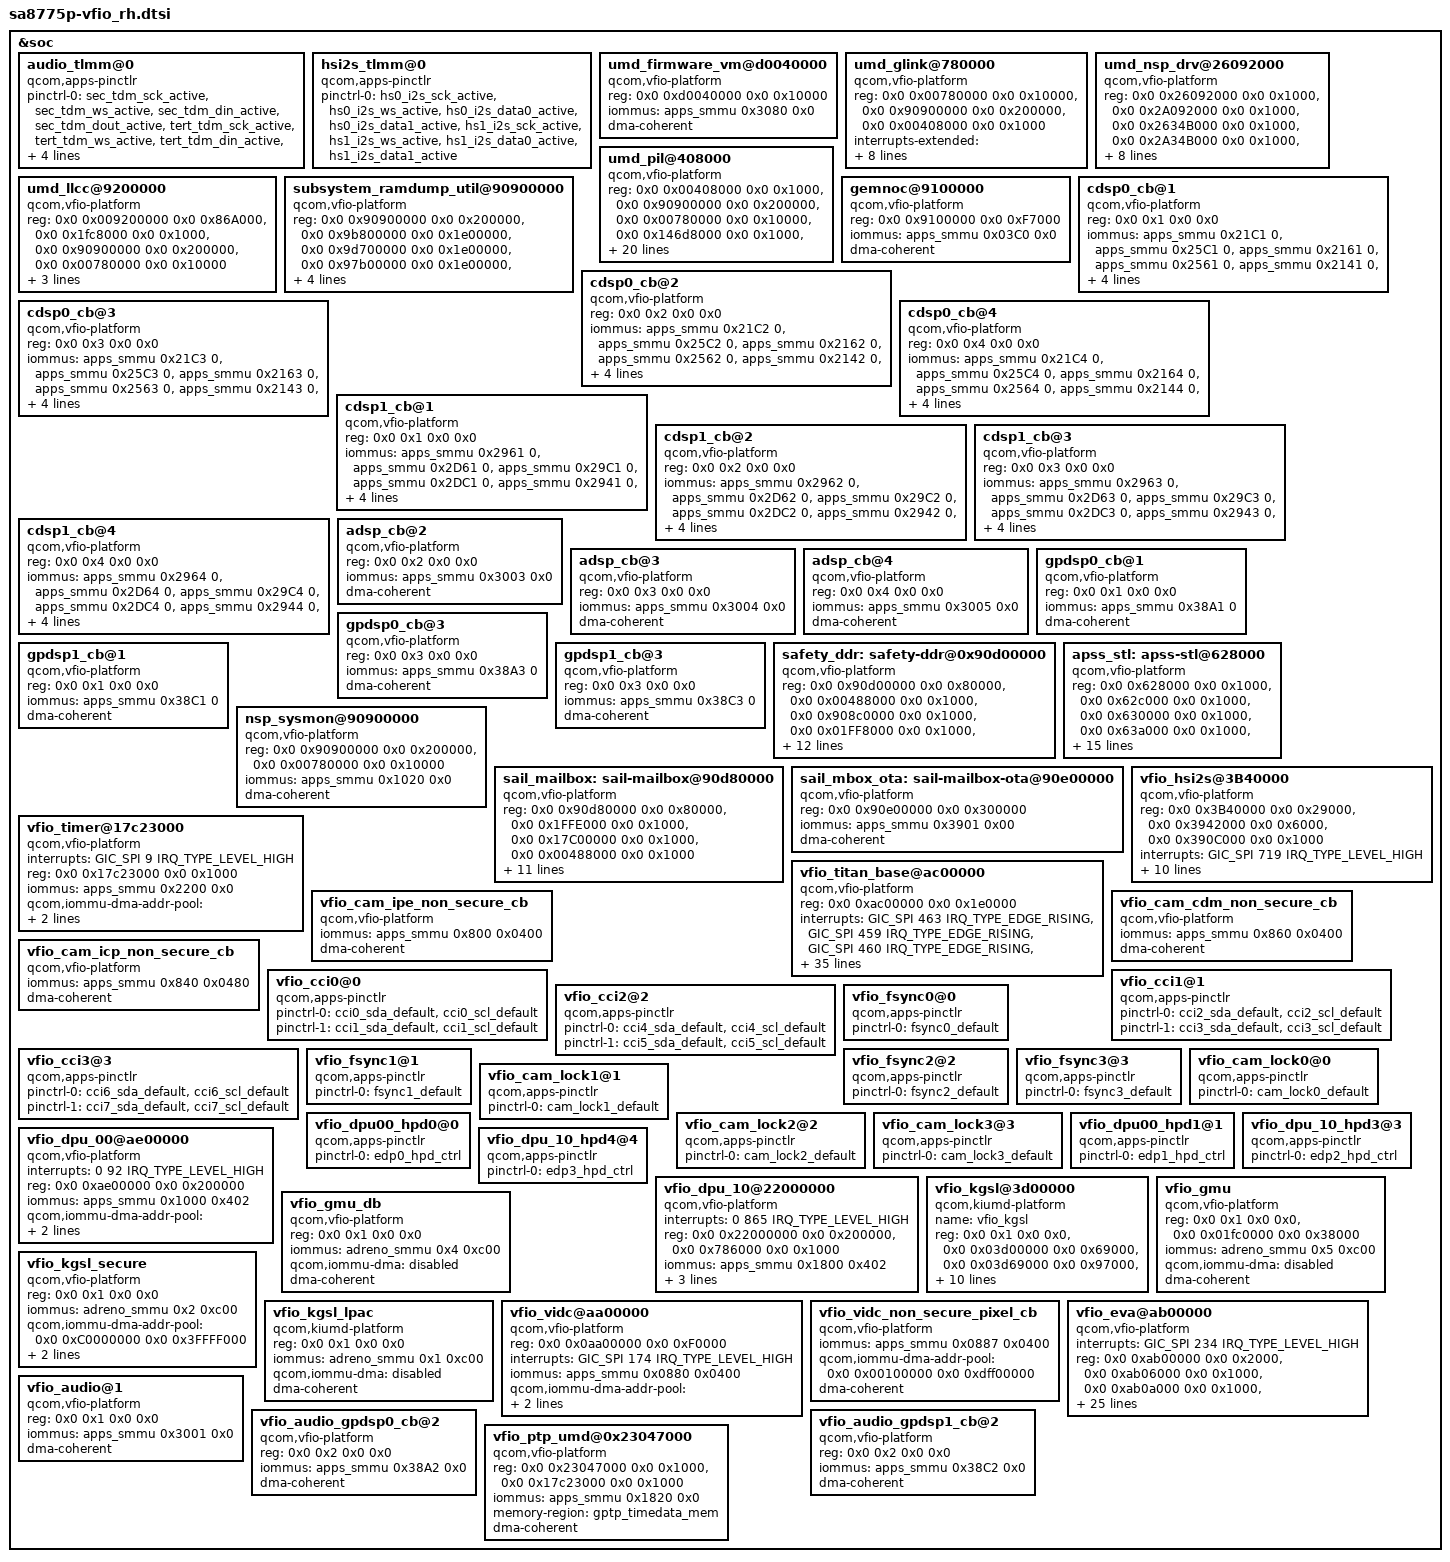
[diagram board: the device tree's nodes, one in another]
// SPDX-License-Identifier: BSD-3-Clause
/*
* Copyright (c) 2024 Qualcomm Innovation Center, Inc. All rights reserved.
*/

&soc {
	audio_tlmm@0 {
		compatible = "qcom,apps-pinctlr";
		pinctrl-names = "default";
		pinctrl-0 = <&sec_tdm_sck_active &sec_tdm_ws_active &sec_tdm_din_active &sec_tdm_dout_active &tert_tdm_sck_active &tert_tdm_ws_active &tert_tdm_din_active &tert_tdm_dout_active &hs2_i2s_sck_active &hs2_i2s_ws_active &hs2_i2s_data0_active &hs2_i2s_data1_active &audio_internal_mclk1_active>;
	};

	hsi2s_tlmm@0 {
		compatible = "qcom,apps-pinctlr";
		pinctrl-names = "default";
		pinctrl-0 = <&hs0_i2s_sck_active &hs0_i2s_ws_active &hs0_i2s_data0_active &hs0_i2s_data1_active &hs1_i2s_sck_active &hs1_i2s_ws_active &hs1_i2s_data0_active &hs1_i2s_data1_active>;
	};

	umd_firmware_vm@d0040000 {
		compatible = "qcom,vfio-platform";
		reg = <0x0 0xd0040000 0x0 0x10000>;
		iommus = <&apps_smmu 0x3080 0x0>;
		dma-coherent;
	};

	umd_glink@780000 {
		compatible = "qcom,vfio-platform";
		reg = <0x0 0x00780000 0x0 0x10000>,
			<0x0 0x90900000 0x0 0x200000>,
			<0x0 0x00408000 0x0 0x1000>;

		interrupts-extended = <&ipcc IPCC_CLIENT_LPASS IPCC_MPROC_SIGNAL_GLINK_QMP IRQ_TYPE_EDGE_RISING>,
				<&ipcc IPCC_CLIENT_CDSP IPCC_MPROC_SIGNAL_GLINK_QMP IRQ_TYPE_EDGE_RISING>,
				<&ipcc IPCC_CLIENT_NSP1  IPCC_MPROC_SIGNAL_GLINK_QMP IRQ_TYPE_EDGE_RISING>,
				<&ipcc IPCC_CLIENT_SLPI  IPCC_MPROC_SIGNAL_GLINK_QMP IRQ_TYPE_EDGE_RISING>,
				<&ipcc IPCC_CLIENT_GPDSP0  IPCC_MPROC_SIGNAL_GLINK_QMP IRQ_TYPE_EDGE_RISING>,
				<&ipcc IPCC_CLIENT_GPDSP1  IPCC_MPROC_SIGNAL_GLINK_QMP IRQ_TYPE_EDGE_RISING>;

		iommus = <&apps_smmu 0x5E0 0x0>;
		dma-coherent;
	};

	umd_nsp_drv@26092000 {
		compatible = "qcom,vfio-platform";
		reg = <0x0 0x26092000 0x0 0x1000>,
			<0x0 0x2A092000 0x0 0x1000>,
			<0x0 0x2634B000 0x0 0x1000>,
			<0x0 0x2A34B000 0x0 0x1000>,
			<0x0 0x26350000 0x0 0x1000>,
			<0x0 0x2A350000 0x0 0x1000>;
		interrupts = <GIC_SPI 867 IRQ_TYPE_LEVEL_HIGH>,
			<GIC_SPI 454 IRQ_TYPE_LEVEL_HIGH>,
			<GIC_SPI 578 IRQ_TYPE_LEVEL_HIGH>,
			<GIC_SPI 798 IRQ_TYPE_LEVEL_HIGH>;
		iommus = <&apps_smmu 0x0D20 0x0>;
		dma-coherent;
	};

	umd_pil@408000 {
		compatible = "qcom,vfio-platform";
		reg = <0x0 0x00408000 0x0 0x1000>,
			<0x0 0x90900000 0x0 0x200000>,
			<0x0 0x00780000 0x0 0x10000>,
			<0x0 0x146d8000 0x0 0x1000>,
			<0x0 0x95700000 0x0 0x500000>,
			<0x0 0x95c00000 0x0 0x1e00000>,
			<0x0 0x9b800000 0x0 0x1e00000>,
			<0x0 0x9fc00000 0x0 0x700000>,
			<0x0 0x9d700000 0x0 0x1e00000>,
			<0x0 0x97b00000 0x0 0x1e00000>,
			<0x0 0x99900000 0x0 0x1e00000>,
			<0x0 0x9D600000 0x0 0x800000>;

		interrupts-extended = <&ipcc IPCC_CLIENT_LPASS IPCC_MPROC_SIGNAL_SMP2P IRQ_TYPE_EDGE_RISING>,
				<&ipcc IPCC_CLIENT_CDSP  IPCC_MPROC_SIGNAL_SMP2P IRQ_TYPE_EDGE_RISING>,
				<&ipcc IPCC_CLIENT_NSP1  IPCC_MPROC_SIGNAL_SMP2P IRQ_TYPE_EDGE_RISING>,
				<&ipcc IPCC_CLIENT_SLPI  IPCC_MPROC_SIGNAL_SMP2P IRQ_TYPE_EDGE_RISING>,
				<&ipcc IPCC_CLIENT_GPDSP0  IPCC_MPROC_SIGNAL_SMP2P IRQ_TYPE_EDGE_RISING>,
				<&ipcc IPCC_CLIENT_GPDSP1  IPCC_MPROC_SIGNAL_SMP2P IRQ_TYPE_EDGE_RISING>,
				<&intc GIC_SPI 486 IRQ_TYPE_LEVEL_HIGH>,
				<&intc GIC_SPI 768 IRQ_TYPE_LEVEL_HIGH>,
				<&intc GIC_SPI 624 IRQ_TYPE_LEVEL_HIGH>;

		iommus = <&apps_smmu 0x2A00 0x0>;
		dma-coherent;
	};

	//Add LLCC node for vfio probe.
	umd_llcc@9200000 {
		compatible = "qcom,vfio-platform";
		reg = <0x0 0x009200000 0x0 0x86A000>,
			<0x0 0x1fc8000 0x0 0x1000>,
			<0x0 0x90900000 0x0 0x200000>,
			<0x0 0x00780000 0x0 0x10000>;
		interrupts = <GIC_SPI 580 IRQ_TYPE_LEVEL_HIGH>;
		iommus = <&apps_smmu 0x2E00 0x0>;
		dma-coherent;
	};

	subsystem_ramdump_util@90900000 {
		compatible = "qcom,vfio-platform";
		reg = <0x0 0x90900000 0x0 0x200000>,
			<0x0 0x9b800000 0x0 0x1e00000>,
			<0x0 0x9d700000 0x0 0x1e00000>,
			<0x0 0x97b00000 0x0 0x1e00000>,
			<0x0 0x99900000 0x0 0x1e00000>,
			<0x0 0x95c00000 0x0 0x1e00000>;

		iommus = <&adreno_smmu 0x407 0xc00>;
		dma-coherent;
	};

	gemnoc@9100000 {
		compatible = "qcom,vfio-platform";
		reg = <0x0 0x9100000 0x0 0xF7000>;
		iommus = <&apps_smmu 0x03C0 0x0>;
		dma-coherent;
	};

	cdsp0_cb@1 {
		compatible = "qcom,vfio-platform";
		reg = <0x0 0x1 0x0 0x0>;
		iommus = <&apps_smmu 0x21C1 0>,
			<&apps_smmu 0x25C1 0>,
			<&apps_smmu 0x2161 0>,
			<&apps_smmu 0x2561 0>,
			<&apps_smmu 0x2141 0>,
			<&apps_smmu 0x2541 0>,
			<&apps_smmu 0x21E1 0>,
			<&apps_smmu 0x25E1 0>,
			<&apps_smmu 0x2181 0>,
			<&apps_smmu 0x2581 0>;
		dma-coherent;
	};

	cdsp0_cb@2 {
		compatible = "qcom,vfio-platform";
		reg = <0x0 0x2 0x0 0x0>;
		iommus = <&apps_smmu 0x21C2 0>,
			<&apps_smmu 0x25C2 0>,
			<&apps_smmu 0x2162 0>,
			<&apps_smmu 0x2562 0>,
			<&apps_smmu 0x2142 0>,
			<&apps_smmu 0x2542 0>,
			<&apps_smmu 0x21E2 0>,
			<&apps_smmu 0x25E2 0>,
			<&apps_smmu 0x2182 0>,
			<&apps_smmu 0x2582 0>;
		dma-coherent;
	};

	cdsp0_cb@3 {
		compatible = "qcom,vfio-platform";
		reg = <0x0 0x3 0x0 0x0>;
		iommus = <&apps_smmu 0x21C3 0>,
			<&apps_smmu 0x25C3 0>,
			<&apps_smmu 0x2163 0>,
			<&apps_smmu 0x2563 0>,
			<&apps_smmu 0x2143 0>,
			<&apps_smmu 0x2543 0>,
			<&apps_smmu 0x21E3 0>,
			<&apps_smmu 0x25E3 0>,
			<&apps_smmu 0x2183 0>,
			<&apps_smmu 0x2583 0>;
		dma-coherent;
	};

	cdsp0_cb@4 {
		compatible = "qcom,vfio-platform";
		reg = <0x0 0x4 0x0 0x0>;
		iommus = <&apps_smmu 0x21C4 0>,
			<&apps_smmu 0x25C4 0>,
			<&apps_smmu 0x2164 0>,
			<&apps_smmu 0x2564 0>,
			<&apps_smmu 0x2144 0>,
			<&apps_smmu 0x2544 0>,
			<&apps_smmu 0x21E4 0>,
			<&apps_smmu 0x25E4 0>,
			<&apps_smmu 0x2184 0>,
			<&apps_smmu 0x2584 0>;
		dma-coherent;
	};

	cdsp1_cb@1 {
		compatible = "qcom,vfio-platform";
		reg = <0x0 0x1 0x0 0x0>;
		iommus = <&apps_smmu 0x2961 0>,
			<&apps_smmu 0x2D61 0>,
			<&apps_smmu 0x29C1 0>,
			<&apps_smmu 0x2DC1 0>,
			<&apps_smmu 0x2941 0>,
			<&apps_smmu 0x2D41 0>,
			<&apps_smmu 0x2981 0>,
			<&apps_smmu 0x2D81 0>,
			<&apps_smmu 0x29E1 0>,
			<&apps_smmu 0x2DE1 0>;
		dma-coherent;
	};

	cdsp1_cb@2 {
		compatible = "qcom,vfio-platform";
		reg = <0x0 0x2 0x0 0x0>;
		iommus = <&apps_smmu 0x2962 0>,
			<&apps_smmu 0x2D62 0>,
			<&apps_smmu 0x29C2 0>,
			<&apps_smmu 0x2DC2 0>,
			<&apps_smmu 0x2942 0>,
			<&apps_smmu 0x2D42 0>,
			<&apps_smmu 0x29E2 0>,
			<&apps_smmu 0x2DE2 0>,
			<&apps_smmu 0x2982 0>,
			<&apps_smmu 0x2D82 0>;
		dma-coherent;
	};

	cdsp1_cb@3 {
		compatible = "qcom,vfio-platform";
		reg = <0x0 0x3 0x0 0x0>;
		iommus = <&apps_smmu 0x2963 0>,
			<&apps_smmu 0x2D63 0>,
			<&apps_smmu 0x29C3 0>,
			<&apps_smmu 0x2DC3 0>,
			<&apps_smmu 0x2943 0>,
			<&apps_smmu 0x2D43 0>,
			<&apps_smmu 0x29E3 0>,
			<&apps_smmu 0x2DE3 0>,
			<&apps_smmu 0x2983 0>,
			<&apps_smmu 0x2D83 0>;
		dma-coherent;
	};

	cdsp1_cb@4 {
		compatible = "qcom,vfio-platform";
		reg = <0x0 0x4 0x0 0x0>;
		iommus = <&apps_smmu 0x2964 0>,
			<&apps_smmu 0x2D64 0>,
			<&apps_smmu 0x29C4 0>,
			<&apps_smmu 0x2DC4 0>,
			<&apps_smmu 0x2944 0>,
			<&apps_smmu 0x2D44 0>,
			<&apps_smmu 0x29E4 0>,
			<&apps_smmu 0x2DE4 0>,
			<&apps_smmu 0x2984 0>,
			<&apps_smmu 0x2D84 0>;
		dma-coherent;
	};

	adsp_cb@2 {
		compatible = "qcom,vfio-platform";
		reg = <0x0 0x2 0x0 0x0>;
		iommus = <&apps_smmu 0x3003 0x0>;
		dma-coherent;
	};

	adsp_cb@3 {
		compatible = "qcom,vfio-platform";
		reg = <0x0 0x3 0x0 0x0>;
		iommus = <&apps_smmu 0x3004 0x0>;
		dma-coherent;
	};

	adsp_cb@4 {
		compatible = "qcom,vfio-platform";
		reg = <0x0 0x4 0x0 0x0>;
		iommus = <&apps_smmu 0x3005 0x0>;
		dma-coherent;
	};

	gpdsp0_cb@1 {
		compatible = "qcom,vfio-platform";
		reg = <0x0 0x1 0x0 0x0>;
		iommus = <&apps_smmu 0x38A1 0>;
		dma-coherent;
	};

	gpdsp0_cb@3 {
		compatible = "qcom,vfio-platform";
		reg = <0x0 0x3 0x0 0x0>;
		iommus = <&apps_smmu 0x38A3 0>;
		dma-coherent;
	};

	gpdsp1_cb@1 {
		compatible = "qcom,vfio-platform";
		reg = <0x0 0x1 0x0 0x0>;
		iommus = <&apps_smmu 0x38C1 0>;
		dma-coherent;
	};

	gpdsp1_cb@3 {
		compatible = "qcom,vfio-platform";
		reg = <0x0 0x3 0x0 0x0>;
		iommus = <&apps_smmu 0x38C3 0>;
		dma-coherent;
	};

	safety_ddr: safety-ddr@0x90d00000 {
		compatible = "qcom,vfio-platform";
		reg = <0x0 0x90d00000 0x0 0x80000>,
			<0x0 0x00488000 0x0 0x1000>,
			<0x0 0x908c0000 0x0 0x1000>,
			<0x0 0x01FF8000 0x0 0x1000>,
			<0x0 0x01FFA000 0x0 0x1000>,
			<0x0 0xDB1DA000 0x0 0x2000>,
			<0x0 0xDB1DB000 0x0 0x1000>,
			<0x0 0x17D00000 0x0 0x1000>,
			<0x0 0x090BD000 0x0 0x1000>;
		iommus = <&apps_smmu 0x3903 0x0>;
		interrupts-extended = <&ipcc1 IPCC_CLIENT_SAIL0 0x1 IRQ_TYPE_EDGE_RISING>,
				      <&ipcc1 IPCC_CLIENT_SAIL1 0x1 IRQ_TYPE_EDGE_RISING>,
				      <&ipcc1 IPCC_CLIENT_SAIL2 0x1 IRQ_TYPE_EDGE_RISING>,
				      <&ipcc1 IPCC_CLIENT_SAIL3 0x1 IRQ_TYPE_EDGE_RISING>;
		dma-coherent;
	};

	apss_stl: apss-stl@628000 {
		compatible = "qcom,vfio-platform";
		reg = <0x0 0x628000 0x0 0x1000>,
			<0x0 0x62c000 0x0 0x1000>,
			<0x0 0x630000 0x0 0x1000>,
			<0x0 0x63a000 0x0 0x1000>,
			<0x0 0x63e000 0x0 0x1000>,
			<0x0 0x3d9a000 0x0 0x1000>,
			<0x0 0x18290000 0x0 0x1000>,
			<0x0 0x18292000 0x0 0x1000>,
			<0x0 0x18294000 0x0 0x1000>,
			<0x0 0x18296000 0x0 0x1000>,
			<0x0 0x18390000 0x0 0x1000>,
			<0x0 0x183a0000 0x0 0x1000>,
			<0x0 0x18420000 0x0 0x1000>,
			<0x0 0x18421000 0x0 0x1000>,
			<0x0 0x18422000 0x0 0x1000>,
			<0x0 0x18423000 0x0 0x1000>,
			<0x0 0x17C21000 0x0 0x1000>;
		iommus = <&apps_smmu 0x3902 0x0>;
		dma-coherent;
	};

	nsp_sysmon@90900000 {
		compatible = "qcom,vfio-platform";
		reg = <0x0 0x90900000 0x0 0x200000>,
			<0x0 0x00780000 0x0 0x10000>;
		iommus = <&apps_smmu 0x1020 0x0>;
		dma-coherent;
	};

	sail_mailbox: sail-mailbox@90d80000 {
		compatible = "qcom,vfio-platform";
		reg = <0x0 0x90d80000 0x0 0x80000>,
		      <0x0 0x1FFE000 0x0 0x1000>,
		      <0x0 0x17C00000 0x0 0x1000>,
		      <0x0 0x00488000 0x0 0x1000>;
		interrupts-extended = <&ipcc1 IPCC_CLIENT_SAIL0 0x2 IRQ_TYPE_EDGE_RISING>,
				      <&ipcc1 IPCC_CLIENT_SAIL0 0x3 IRQ_TYPE_EDGE_RISING>,
				      <&ipcc1 IPCC_CLIENT_SAIL0 0x4 IRQ_TYPE_EDGE_RISING>,
				      <&ipcc1 IPCC_CLIENT_SAIL0 0x5 IRQ_TYPE_EDGE_RISING>,
				      <&ipcc1 IPCC_CLIENT_SAIL0 0x6 IRQ_TYPE_EDGE_RISING>,
				      <&ipcc1 IPCC_CLIENT_SAIL0 0x7 IRQ_TYPE_EDGE_RISING>,
				      <&ipcc1 IPCC_CLIENT_SAIL2 0x8 IRQ_TYPE_EDGE_RISING>,
				      <&ipcc1 IPCC_CLIENT_SAIL1 0x9 IRQ_TYPE_EDGE_RISING>;
		iommus = <&apps_smmu 0x3900 0x00>;
		dma-coherent;
	};

	sail_mbox_ota: sail-mailbox-ota@90e00000 {
		compatible = "qcom,vfio-platform";
		reg = <0x0 0x90e00000 0x0 0x300000>;
		iommus = <&apps_smmu 0x3901 0x00>;
		dma-coherent;
	};

	vfio_hsi2s@3B40000 {
		compatible = "qcom,vfio-platform";
		reg = <0x0 0x3B40000 0x0 0x29000>,
		    <0x0 0x3942000 0x0 0x6000>,
		    <0x0 0x390C000 0x0 0x1000>;
		reg-names = "lpa_if", "lpass_core_cc_hs_if", "lpass_core_cc_i2s_if_ctl";
		interrupts = <GIC_SPI 719 IRQ_TYPE_LEVEL_HIGH>;
		number-of-rate-detectors = <2>;
		rate-detector-interfaces = <0 1>;
		number-of-interfaces = <2>;
		qcom,smmu-version = <2>;
		qcom,smmu-enabled;
		iommus = <&apps_smmu 0x303C 0x1>,
		       <&apps_smmu 0x303A 0x4>,
		       <&apps_smmu 0x303B 0x0>;
		qcom,iommu-dma-addr-pool = <0x0 0x0 0x0 0xFFFFFFFF>;
		dma-coherent;
	};

	vfio_timer@17c23000 {
		compatible = "qcom,vfio-platform";
		interrupts = <GIC_SPI 9 IRQ_TYPE_LEVEL_HIGH>;
		reg = <0x0 0x17c23000 0x0 0x1000>;
		iommus = <&apps_smmu 0x2200 0x0>;
		qcom,iommu-dma-addr-pool = <0x0 0x60002000 0x0 0x1FFFE000>;
		dma-coherent;
	};

	vfio_titan_base@ac00000 {
		compatible = "qcom,vfio-platform";
		reg = <0x0 0xac00000 0x0 0x1e0000>;
		interrupts = <GIC_SPI 463 IRQ_TYPE_EDGE_RISING>,
			<GIC_SPI 459 IRQ_TYPE_EDGE_RISING>,
			<GIC_SPI 460 IRQ_TYPE_EDGE_RISING>,
			<GIC_SPI 271 IRQ_TYPE_EDGE_RISING>,
			<GIC_SPI 651 IRQ_TYPE_EDGE_RISING>,
			<GIC_SPI 771 IRQ_TYPE_EDGE_RISING>,
			<GIC_SPI 477 IRQ_TYPE_EDGE_RISING>,
			<GIC_SPI 478 IRQ_TYPE_EDGE_RISING>,
			<GIC_SPI 479 IRQ_TYPE_EDGE_RISING>,
			<GIC_SPI 448 IRQ_TYPE_EDGE_RISING>,
			<GIC_SPI 469 IRQ_TYPE_EDGE_RISING>,
			<GIC_SPI 360 IRQ_TYPE_EDGE_RISING>,
			<GIC_SPI 761 IRQ_TYPE_EDGE_RISING>,
			<GIC_SPI 760 IRQ_TYPE_EDGE_RISING>,
			<GIC_SPI 605 IRQ_TYPE_EDGE_RISING>,
			<GIC_SPI 465 IRQ_TYPE_EDGE_RISING>,
			<GIC_SPI 467 IRQ_TYPE_EDGE_RISING>,
			<GIC_SPI 563 IRQ_TYPE_EDGE_RISING>,
			<GIC_SPI 562 IRQ_TYPE_EDGE_RISING>,
			<GIC_SPI 468 IRQ_TYPE_EDGE_RISING>,
			<GIC_SPI 359 IRQ_TYPE_EDGE_RISING>,
			<GIC_SPI 759 IRQ_TYPE_EDGE_RISING>,
			<GIC_SPI 758 IRQ_TYPE_EDGE_RISING>,
			<GIC_SPI 604 IRQ_TYPE_EDGE_RISING>,
			<GIC_SPI 565 IRQ_TYPE_EDGE_RISING>,
			<GIC_SPI 564 IRQ_TYPE_EDGE_RISING>,
			<GIC_SPI 545 IRQ_TYPE_EDGE_RISING>,
			<GIC_SPI 546 IRQ_TYPE_EDGE_RISING>,
			<GIC_SPI 547 IRQ_TYPE_EDGE_RISING>,
			<GIC_SPI 470 IRQ_TYPE_EDGE_RISING>,
			<GIC_SPI 471 IRQ_TYPE_EDGE_RISING>,
			<GIC_SPI 543 IRQ_TYPE_EDGE_RISING>,
			<GIC_SPI 544 IRQ_TYPE_EDGE_RISING>,
			<GIC_SPI 567 IRQ_TYPE_EDGE_RISING>,
			<GIC_SPI 566 IRQ_TYPE_EDGE_RISING>,
			<GIC_SPI 366 IRQ_TYPE_EDGE_RISING>;
		iommus = <&apps_smmu 0x3400 0x0020>;
		dma-coherent;
	};

	vfio_cam_ipe_non_secure_cb {
		compatible = "qcom,vfio-platform";
		iommus = <&apps_smmu 0x800 0x0400>;
		dma-coherent;
	};

	vfio_cam_cdm_non_secure_cb {
		compatible = "qcom,vfio-platform";
		iommus = <&apps_smmu 0x860 0x0400>;
		dma-coherent;
	};

	vfio_cam_icp_non_secure_cb {
		compatible = "qcom,vfio-platform";
		iommus = <&apps_smmu 0x840 0x0480>;
		dma-coherent;
	};

	vfio_cci0@0 {
		compatible = "qcom,apps-pinctlr";
		pinctrl-names = "default","default";
		pinctrl-0 = <&cci0_sda_default &cci0_scl_default>;
		pinctrl-1 = <&cci1_sda_default &cci1_scl_default>;
	};

	vfio_cci1@1 {
		compatible = "qcom,apps-pinctlr";
		pinctrl-names = "default","default";
		pinctrl-0 = <&cci2_sda_default &cci2_scl_default>;
		pinctrl-1 = <&cci3_sda_default &cci3_scl_default>;
	};

	vfio_cci2@2 {
		compatible = "qcom,apps-pinctlr";
		pinctrl-names = "default","default";
		pinctrl-0 = <&cci4_sda_default &cci4_scl_default>;
		pinctrl-1 = <&cci5_sda_default &cci5_scl_default>;
	};

	vfio_cci3@3 {
		compatible = "qcom,apps-pinctlr";
		pinctrl-names = "default","default";
		pinctrl-0 = <&cci6_sda_default &cci6_scl_default>;
		pinctrl-1 = <&cci7_sda_default &cci7_scl_default>;
	};

	vfio_fsync0@0 {
		compatible = "qcom,apps-pinctlr";
		pinctrl-names = "default";
		pinctrl-0 = <&fsync0_default>;
	};

	vfio_fsync1@1 {
		compatible = "qcom,apps-pinctlr";
		pinctrl-names = "default";
		pinctrl-0 = <&fsync1_default>;
	};

	vfio_fsync2@2 {
		compatible = "qcom,apps-pinctlr";
		pinctrl-names = "default";
		pinctrl-0 = <&fsync2_default>;
	};

	vfio_fsync3@3 {
		compatible = "qcom,apps-pinctlr";
		pinctrl-names = "default";
		pinctrl-0 = <&fsync3_default>;
	};

	vfio_cam_lock0@0 {
		compatible = "qcom,apps-pinctlr";
		pinctrl-names = "default";
		pinctrl-0 = <&cam_lock0_default>;
	};

	vfio_cam_lock1@1 {
		compatible = "qcom,apps-pinctlr";
		pinctrl-names = "default";
		pinctrl-0 = <&cam_lock1_default>;
	};

	vfio_cam_lock2@2 {
		compatible = "qcom,apps-pinctlr";
		pinctrl-names = "default";
		pinctrl-0 = <&cam_lock2_default>;
	};

	vfio_cam_lock3@3 {
		compatible = "qcom,apps-pinctlr";
		pinctrl-names = "default";
		pinctrl-0 = <&cam_lock3_default>;
	};

	vfio_dpu00_hpd0@0 {
		compatible = "qcom,apps-pinctlr";
		pinctrl-names = "default";
		pinctrl-0 = <&edp0_hpd_ctrl>;
	};

	vfio_dpu00_hpd1@1 {
		compatible = "qcom,apps-pinctlr";
		pinctrl-names = "default";
		pinctrl-0 = <&edp1_hpd_ctrl>;
	};

	vfio_dpu_00@ae00000 {
		compatible = "qcom,vfio-platform";
		interrupts = <0 92 IRQ_TYPE_LEVEL_HIGH>;
		reg = <0x0 0xae00000 0x0 0x200000>;
		iommus = <&apps_smmu 0x1000 0x402>;
		qcom,iommu-dma-addr-pool = <0x0 0x0 0x0 0xffffffff>;
		dma-coherent;
	};

	vfio_dpu_10_hpd3@3 {
		compatible = "qcom,apps-pinctlr";
		pinctrl-names = "default";
		pinctrl-0 = <&edp2_hpd_ctrl>;
	};

	vfio_dpu_10_hpd4@4 {
		compatible = "qcom,apps-pinctlr";
		pinctrl-names = "default";
		pinctrl-0 = <&edp3_hpd_ctrl>;
	};

	vfio_dpu_10@22000000 {
		compatible = "qcom,vfio-platform";
		interrupts = <0 865 IRQ_TYPE_LEVEL_HIGH>;
		reg = <0x0 0x22000000 0x0 0x200000>,
			<0x0 0x786000 0x0 0x1000>;
		iommus = <&apps_smmu 0x1800 0x402>;
		qcom,iommu-dma-addr-pool = <0x0 0x0 0x0 0xffffffff>;
		dma-coherent;
	};

	vfio_kgsl@3d00000 {
		name = "vfio_kgsl";
		compatible = "qcom,kiumd-platform";

		reg = <0x0 0x1 0x0 0x0>,
			<0x0 0x03d00000 0x0 0x69000>,
			<0x0 0x03d69000 0x0 0x97000>,
			<0x0 0x0b210000 0x0 0x400000>,
			<0x0 0x00780000 0x0 0x7000>,
			<0x0 0x01fc8000 0x0 0x1000>,
			<0x0 0x01fc0000 0x0 0x30000>;
		reg-names = "dummy", "gpu_reg", "gmu_reg",
			"rpmh_pdc", "security_control_core",
			"tcsr_hwver_reg", "tcsr_tcsr_reg";

		interrupts = <0 300 IRQ_TYPE_LEVEL_HIGH>,
			<0 304 IRQ_TYPE_LEVEL_HIGH>,
			<0 305 IRQ_TYPE_LEVEL_HIGH>;
		interrupt-names = "kgsl_3d0_irq", "kgsl_hfi_irq",
				"kgsl_gmu_irq";

		iommus = <&adreno_smmu 0x0 0xc00>;
		qcom,iommu-dma = "disabled";
		dma-coherent;
	};

	vfio_gmu {
		compatible = "qcom,vfio-platform";
		reg = <0x0 0x1 0x0 0x0>,
			<0x0 0x01fc0000 0x0 0x38000>;
		reg-names = "dummy", "tcsr_tcsr_reg";
		iommus = <&adreno_smmu 0x5 0xc00>;
		qcom,iommu-dma = "disabled";
		dma-coherent;
	};

	vfio_gmu_db {
		compatible = "qcom,vfio-platform";
		reg = <0x0 0x1 0x0 0x0>;
		iommus = <&adreno_smmu 0x4 0xc00>;
		qcom,iommu-dma = "disabled";
		dma-coherent;
	};

	vfio_kgsl_secure {
		compatible = "qcom,vfio-platform";
		reg = <0x0 0x1 0x0 0x0>;
		// switch to secure CB once ready
		iommus = <&adreno_smmu 0x2 0xc00>;
		qcom,iommu-dma-addr-pool = <0x0 0xC0000000 0x0 0x3FFFF000>;
		qcom,iommu-dma = "disabled";
		dma-coherent;
	};

	vfio_kgsl_lpac {
		compatible = "qcom,kiumd-platform";
		reg = <0x0 0x1 0x0 0x0>;
		iommus = <&adreno_smmu 0x1 0xc00>;
		qcom,iommu-dma = "disabled";
		dma-coherent;
	};

	vfio_vidc@aa00000 {
		compatible = "qcom,vfio-platform";
		reg = <0x0 0x0aa00000 0x0 0xF0000>;
		interrupts = <GIC_SPI 174 IRQ_TYPE_LEVEL_HIGH>;

		/* MMU: non_secure_cb */
		iommus = <&apps_smmu 0x0880 0x0400>;
		qcom,iommu-dma-addr-pool = <0x0 0x25800000 0x0 0xba800000>;
		dma-coherent;
	};

	vfio_vidc_non_secure_pixel_cb {
		compatible = "qcom,vfio-platform";
		iommus = <&apps_smmu 0x0887 0x0400>;
		qcom,iommu-dma-addr-pool = <0x0 0x00100000 0x0 0xdff00000>;
		dma-coherent;
	};

	vfio_eva@ab00000 {
		compatible = "qcom,vfio-platform";
		interrupts = <GIC_SPI 234 IRQ_TYPE_LEVEL_HIGH>;
		reg = <0x0 0xab00000 0x0 0x2000>,    //CVP0_CVP_TOP_PHYS_ADDR
		      <0x0 0xab06000 0x0 0x1000>,    //CVP_DMA0_PHYS_ADDR
		      <0x0 0xab0a000 0x0 0x1000>,    //CVP_FDU0_ECC_PHYS_ADDR <0xab0a000 0x400>
		      <0x0 0xab0a000 0x0 0x3000>,    //CVP_DMA0_ECC_PHYS_ADDR <0xab0a800 0x2000>
		      <0x0 0xab0c000 0x0 0x3000>,    //CVP_MPU0_ECC_PHYS_ADDR <0xab0c800 0x2000>
		      <0x0 0xab20000 0x0 0x2000>,    //CVP1_CVP_TOP_PHYS_ADDR
		      <0x0 0xab26000 0x0 0x1000>,    //CVP_DMA1_PHYS_ADDR
		      <0x0 0xab2a000 0x0 0x1000>,    //CVP_FDU1_ECC_PHYS_ADDR <0xab2a000 0x400>
		      <0x0 0xab2a000 0x0 0x3000>,    //CVP_DMA1_ECC_PHYS_ADDR <0xab2a800 0x2000>
		      <0x0 0xab2c000 0x0 0x3000>,    //CVP_MPU1_ECC_PHYS_ADDR <0xab2c800 0x2000>
		      <0x0 0xab10000 0x0 0x10000>,   //CVP_NOC_VIDEO_B_PHYS_ADDR <0xab10000 0xf580>
		      <0x0 0xab1F000 0x0 0x1000>,    //AON_CVP_NOC_RESET_PHYS_ADDR <0xab1F800 0x800>
		      <0x0 0xabb0000 0x0 0x2000>,    //CVP_IRIS_WRAPPER_PHYS_ADDR
		      <0x0 0xabc2000 0x0 0x1000>,    //CVP_TZ0_PHYS_ADDR
		      <0x0 0xabc3000 0x0 0x1000>,    //CVP_TZ1_PHYS_ADDR
		      <0x0 0xabd0000 0x0 0x2000>,    //CVP_IRIS_CPU_NOC_PHYS_ADDR <0xabd0080 0x1f80>
		      <0x0 0x110000  0x0 0x1e0000>,  //GCC_CLK_CTL_REG_PHYS_ADDR
		      <0x0 0xab04000 0x0 0x1000>,    //CVP_FDU0_CVP_FDU_PHYS_ADDR <0xab04000 0x400>
		      <0x0 0xab04000 0x0 0x1000>,    //CVP_MPU0_CVP_MPU_PHYS_ADDR <0xab04400 0x400>
		      <0x0 0xab90000 0x0 0x1000>,    //CVP_CPU_WD_PHYS_ADDR
		      <0x0 0xabc0000 0x0 0x2000>,    //CVP_TZ_WRAPPER_PHYS_ADDR
		      <0x0 0xaba0000 0x0 0x1000>,    //CVP_CPU_CS_PHYS_ADDR
		      <0x0 0xabe0000 0x0 0xf000>,    //CVP_AON_PHYS_ADDR
		      <0x0 0xabf0000 0x0 0x10000>;   //CVP_VIDEO_CC_VIDEO_PHYS_ADDR
		iommus = <&apps_smmu 0x08A0 0x400>;
		qcom,iommu-dma-addr-pool = <0x0 0x4b000000 0x0 0x90000000>;
		dma-coherent;
	};

	vfio_audio@1 {
		compatible = "qcom,vfio-platform";
		reg = <0x0 0x1 0x0 0x0>;
		iommus = <&apps_smmu 0x3001 0x0>;
		dma-coherent;
	};

	vfio_audio_gpdsp0_cb@2 {
		compatible = "qcom,vfio-platform";
		reg = <0x0 0x2 0x0 0x0>;
		iommus = <&apps_smmu 0x38A2 0x0>;
		dma-coherent;
	};

	vfio_audio_gpdsp1_cb@2 {
		compatible = "qcom,vfio-platform";
		reg = <0x0 0x2 0x0 0x0>;
		iommus = <&apps_smmu 0x38C2 0x0>;
		dma-coherent;
	};

	vfio_ptp_umd@0x23047000 {
		compatible = "qcom,vfio-platform";
		reg = <0x0 0x23047000 0x0 0x1000>,
			<0x0 0x17c23000 0x0 0x1000>;
		iommus = <&apps_smmu 0x1820 0x0>;
		memory-region = <&gptp_timedata_mem>;
		dma-coherent;
	};
};
